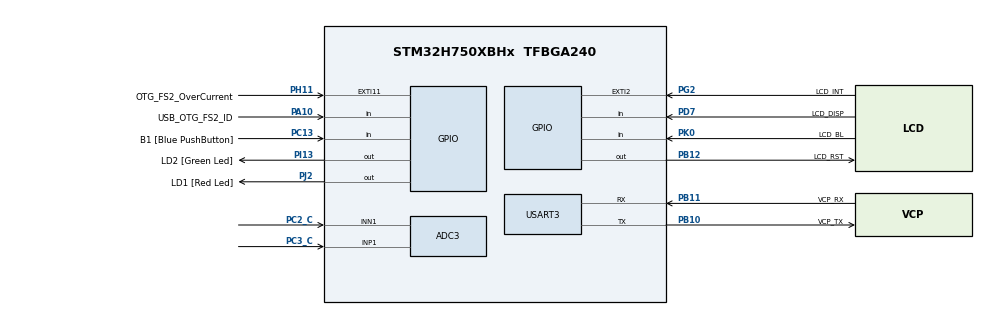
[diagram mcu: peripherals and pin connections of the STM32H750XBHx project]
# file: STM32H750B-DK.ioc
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ADC3.Channel-0\#ChannelRegularConversion=ADC_CHANNEL_1
ADC3.NbrOfConversionFlag=1
ADC3.OffsetNumber-0\#ChannelRegularConversion=ADC_OFFSET_NONE
ADC3.Rank-0\#ChannelRegularConversion=1
ADC3.SamplingTime-0\#ChannelRegularConversion=ADC_SAMPLETIME_1CYCLE_5
ADC3.SingleDiff-0\#ChannelRegularConversion=ADC_DIFFERENTIAL_ENDED
board=STM32H750B-DK
CORTEX_M7.AccessPermission-Cortex_Memory_Protection_Unit_Region0_Settings=MPU_REGION_FULL_ACCESS
CORTEX_M7.AccessPermission-Cortex_Memory_Protection_Unit_Region1_Settings=MPU_REGION_FULL_ACCESS
CORTEX_M7.BaseAddress-Cortex_Memory_Protection_Unit_Region0_Settings=0x90000000
CORTEX_M7.BaseAddress-Cortex_Memory_Protection_Unit_Region1_Settings=0xD0000000
CORTEX_M7.CPU_DCache=Enabled
CORTEX_M7.CPU_ICache=Enabled
CORTEX_M7.Enable-Cortex_Memory_Protection_Unit_Region0_Settings=MPU_REGION_ENABLE
CORTEX_M7.Enable-Cortex_Memory_Protection_Unit_Region1_Settings=MPU_REGION_ENABLE
CORTEX_M7.IsBufferable-Cortex_Memory_Protection_Unit_Region0_Settings=MPU_ACCESS_BUFFERABLE
CORTEX_M7.IsBufferable-Cortex_Memory_Protection_Unit_Region1_Settings=MPU_ACCESS_BUFFERABLE
CORTEX_M7.IsCacheable-Cortex_Memory_Protection_Unit_Region0_Settings=MPU_ACCESS_CACHEABLE
CORTEX_M7.IsCacheable-Cortex_Memory_Protection_Unit_Region1_Settings=MPU_ACCESS_CACHEABLE
CORTEX_M7.MPU_Control=MPU_PRIVILEGED_DEFAULT
CORTEX_M7.Size-Cortex_Memory_Protection_Unit_Region0_Settings=MPU_REGION_SIZE_128MB
CORTEX_M7.Size-Cortex_Memory_Protection_Unit_Region1_Settings=MPU_REGION_SIZE_8MB
Mcu.Family=STM32H7
Mcu.Name=STM32H750XBHx
Mcu.Package=TFBGA240
NVIC.PriorityGroup=NVIC_PRIORITYGROUP_4
PA0_C.Signal=ADCx_INP0
PA1_C.Signal=ADCx_INP1
PA1.GPIO_Label=MII_RX_CLK
PA1.Signal=ETH_RX_CLK
PA10.GPIO_Label=USB_OTG_FS2_ID
PA10.Signal=GPIO_Input
PA11.GPIO_Label=USB_OTG_FS2_N
PA11.Signal=USB_OTG_FS_DM
PA12.GPIO_Label=USB_OTG_FS2_P
PA12.Signal=USB_OTG_FS_DP
PA2.GPIO_Label=MII_MDIO
PA2.Signal=ETH_MDIO
PA6.Signal=S_TIM13_CH1
PA7.GPIO_Label=MII_RX_DV
PA7.Signal=ETH_RX_DV
PA8.Signal=S_TIM1_CH1
PA9.GPIO_Label=VBUS_FS2
PA9.Signal=USB_OTG_FS_VBUS
PB0.GPIO_Label=MII_RX_D2
PB0.Signal=ETH_RXD2
PB1.GPIO_Label=MII_RX_D3
PB1.Signal=ETH_RXD3
PB10.GPIO_Label=VCP_TX
PB10.Mode=Asynchronous
PB10.Signal=USART3_TX
PB11.GPIO_Label=VCP_RX
PB11.GPIO_PuPd=GPIO_PULLUP
PB11.Mode=Asynchronous
PB11.Signal=USART3_RX
PB12.GPIO_Label=LCD_RST
PB12.Signal=GPIO_Output
PB13.GPIO_Label=FDCAN2_TX
PB13.Signal=FDCAN2_TX
PB15.Signal=SPI2_MOSI
PB4\ (NJTRST).Signal=SPI2_NSS
PB5.GPIO_Label=FDCAN2_RX
PB5.Signal=FDCAN2_RX
PB6.Signal=QUADSPI_BK1_NCS
PB8.GPIO_Label=SDIO1_D4
PB8.Signal=SDMMC1_D4
PB9.GPIO_Label=SDIO1_D5
PB9.Signal=SDMMC1_D5
PC0.Signal=ADCx_INP10
PC1.GPIO_Label=MII_MDC
PC1.Signal=ETH_MDC
PC10.GPIO_Label=SDIO1_D2
PC10.Signal=SDMMC1_D2
PC11.GPIO_Label=SDIO1_D3
PC11.Signal=SDMMC1_D3
PC12.GPIO_Label=SDIO1_CK
PC12.Signal=SDMMC1_CK
PC13.GPIO_Label=B1 [Blue PushButton]
PC13.Signal=GPIO_Input
PC14-OSC32_IN\ (OSC32_IN).GPIO_Label=OSC32_IN
PC14-OSC32_IN\ (OSC32_IN).Mode=LSE-External-Oscillator
PC14-OSC32_IN\ (OSC32_IN).Signal=RCC_OSC32_IN
PC15-OSC32_OUT\ (OSC32_OUT).GPIO_Label=OSC32_OUT
PC15-OSC32_OUT\ (OSC32_OUT).Mode=LSE-External-Oscillator
PC15-OSC32_OUT\ (OSC32_OUT).Signal=RCC_OSC32_OUT
PC2_C.Signal=SharedAnalog_PC2
PC2.GPIO_Label=MII_TXD2
PC2.Signal=ETH_TXD2
PC3_C.Mode=IN1-Differential
PC3_C.Signal=ADC3_INP1
PC3.GPIO_Label=MII_TX_CLK
PC3.Signal=ETH_TX_CLK
PC4.GPIO_Label=MII_RXD0
PC4.Signal=ETH_RXD0
PC5.GPIO_Label=MII_RXD1
PC5.Signal=ETH_RXD1
PC6.GPIO_Label=SDIO1_D6
PC6.Signal=SDMMC1_D6
PC7.GPIO_Label=SDIO1_D7
PC7.Signal=SDMMC1_D7
PC8.GPIO_Label=SDIO1_D0
PC8.Signal=SDMMC1_D0
PC9.GPIO_Label=SDIO1_D1
PC9.Signal=SDMMC1_D1
PD0.Signal=FMC_D2_DA2
PD1.Signal=FMC_D3_DA3
PD10.Signal=FMC_D15_DA15
PD11.Signal=QUADSPI_BK1_IO0
PD14.Signal=FMC_D0_DA0
PD15.Signal=FMC_D1_DA1
PD2.GPIO_Label=SDIO1_CMD
PD2.Signal=SDMMC1_CMD
PD3.Signal=SPI2_SCK
PD7.GPIO_Label=LCD_DISP
PD7.Signal=GPIO_Input
PD8.Signal=FMC_D13_DA13
PD9.Signal=FMC_D14_DA14
PE0.Signal=FMC_NBL0
PE1.Signal=FMC_NBL1
PE10.Signal=FMC_D7_DA7
PE11.Signal=FMC_D8_DA8
PE12.Signal=FMC_D9_DA9
PE13.Signal=FMC_D10_DA10
PE14.Signal=FMC_D11_DA11
PE15.Signal=FMC_D12_DA12
PE2.GPIO_Label=MII_TXD3
PE2.Signal=ETH_TXD3
PE4.Signal=SAI4_D2
PE5.Signal=SAI4_CK2
PE7.Signal=FMC_D4_DA4
PE8.Signal=FMC_D5_DA5
PE9.Signal=FMC_D6_DA6
PF0.Signal=FMC_A0
PF1.Signal=FMC_A1
PF10.Signal=QUADSPI_CLK
PF11.Signal=FMC_SDNRAS
PF12.Signal=FMC_A6
PF13.Signal=FMC_A7
PF14.Signal=FMC_A8
PF15.Signal=FMC_A9
PF2.Signal=FMC_A2
PF3.Signal=FMC_A3
PF4.Signal=FMC_A4
PF5.Signal=FMC_A5
PF6.Signal=QUADSPI_BK1_IO3
PF7.Signal=QUADSPI_BK1_IO2
PF8.Signal=ADC3_INP7
PF9.Signal=QUADSPI_BK1_IO1
PG0.Signal=FMC_A10
PG1.Signal=FMC_A11
PG10.Signal=SAI2_SD_B
PG11.GPIO_Label=MII_TX_EN
PG11.Signal=ETH_TX_EN
PG12.GPIO_Label=MII_TXD1
PG12.Signal=ETH_TXD1
PG13.GPIO_Label=MII_TXD0
PG13.Signal=ETH_TXD0
PG15.Signal=FMC_SDNCAS
PG2.GPIO_Label=LCD_INT
PG2.Signal=GPXTI2
PG4.Signal=FMC_A14_BA0
PG5.Signal=FMC_A15_BA1
PG8.Signal=FMC_SDCLK
PH0-OSC_IN\ (PH0).GPIO_Label=OSC_IN
PH0-OSC_IN\ (PH0).Mode=HSE-External-Oscillator
PH0-OSC_IN\ (PH0).Signal=RCC_OSC_IN
PH1-OSC_OUT\ (PH1).GPIO_Label=OSC_OUT
PH1-OSC_OUT\ (PH1).Mode=HSE-External-Oscillator
PH1-OSC_OUT\ (PH1).Signal=RCC_OSC_OUT
PH11.GPIO_Label=OTG_FS2_OverCurrent
PH11.Signal=GPXTI11
PH13.GPIO_Label=FDCAN1_TX
PH13.Signal=FDCAN1_TX
PH14.GPIO_Label=FDCAN1_RX
PH14.Signal=FDCAN1_RX
PH15.Signal=TIM8_CH3N
PH2.GPIO_Label=MII_CRS
PH2.Signal=ETH_CRS
PH3.GPIO_Label=MII_COL
PH3.Signal=ETH_COL
PH5.Signal=FMC_SDNWE
PH6.Signal=FMC_SDNE1
PH7.Signal=FMC_SDCKE1
PH9.Signal=LTDC_R3
PI0.Signal=LTDC_G5
PI1.Signal=LTDC_G6
PI10.GPIO_Label=MII_RX_ER
PI10.Signal=ETH_RX_ER
PI12.Signal=LTDC_HSYNC
PI13.GPIO_Label=LD2 [Green Led]
PI13.Signal=GPIO_Output
PI14.Signal=LTDC_CLK
PI15.Signal=LTDC_R0
PI2.Signal=SPI2_MISO
PI4.Signal=SAI2_MCLK_A
PI5.Signal=SAI2_SCK_A
PI6.Signal=SAI2_SD_A
PI7.Signal=SAI2_FS_A
PI9.Signal=LTDC_VSYNC
PJ0.Signal=LTDC_R1
PJ1.Signal=LTDC_R2
PJ10.Signal=LTDC_G3
PJ11.Signal=LTDC_G4
PJ12.Signal=LTDC_B0
PJ13.Signal=LTDC_B1
PJ14.Signal=LTDC_B2
PJ15.GPIO_Label=LCD_DISP
PJ15.Signal=LTDC_B3
PJ2.GPIO_Label=LD1 [Red Led]
PJ2.Signal=GPIO_Output
PJ3.Signal=LTDC_R4
PJ4.Signal=LTDC_R5
PJ5.Signal=LTDC_R6
PJ6.Signal=LTDC_R7
PJ7.Signal=LTDC_G0
PJ8.Signal=LTDC_G1
PJ9.Signal=LTDC_G2
PK0.GPIO_Label=LCD_BL
PK0.Signal=GPIO_Input
PK2.Signal=LTDC_G7
PK3.Signal=LTDC_B4
PK4.Signal=LTDC_B5
PK5.Signal=LTDC_B6
PK6.Signal=LTDC_B7
PK7.Signal=LTDC_DE
ProjectManager.HeapSize=0x800
ProjectManager.StackSize=0x800
ProjectManager.TargetToolchain=STM32CubeIDE
RCC.ADCCLockSelection=RCC_ADCCLKSOURCE_PLL3
RCC.ADCFreq_Value=80000000
RCC.APB1Freq_Value=120000000
RCC.APB2Freq_Value=120000000
RCC.APB3Freq_Value=120000000
RCC.APB4Freq_Value=120000000
RCC.CortexFreq_Value=480000000
RCC.D1PPRE=RCC_APB3_DIV2
RCC.D2PPRE1=RCC_APB1_DIV2
RCC.D2PPRE2=RCC_APB2_DIV2
RCC.D3PPRE=RCC_APB4_DIV2
RCC.DIVM1=5
RCC.DIVM2=2
RCC.DIVM3=5
RCC.DIVN1=192
RCC.DIVN2=24
RCC.DIVN3=32
RCC.DIVP2=4
RCC.DIVQ1=4
RCC.HCLKFreq_Value=240000000
RCC.HPRE=RCC_HCLK_DIV2
RCC.PLL2FRACN=0
RCC.PLL3FRACN=0
RCC.PLLFRACN=0
RCC.PLLSourceVirtual=RCC_PLLSOURCE_HSE
RCC.PWR_Regulator_Voltage_Scale=PWR_REGULATOR_VOLTAGE_SCALE0
RCC.SAI1CLockSelection=RCC_SAI1CLKSOURCE_PLL2
RCC.SYSCLKFreq_VALUE=480000000
RCC.SYSCLKSource=RCC_SYSCLKSOURCE_PLLCLK
RCC.USBCLockSelection=RCC_USBCLKSOURCE_HSI48
RCC.USBFreq_Value=48000000
SH.ADCx_INP0.0=ADC1_INP0
SH.ADCx_INP0.1=ADC2_INP0
SH.ADCx_INP1.0=ADC1_INP1
SH.ADCx_INP1.1=ADC2_INP1
SH.ADCx_INP10.0=ADC1_INP10
SH.ADCx_INP10.1=ADC3_INP10
SH.FMC_A0.0=FMC_A0
SH.FMC_A1.0=FMC_A1
SH.FMC_A10.0=FMC_A10
SH.FMC_A11.0=FMC_A11
SH.FMC_A14_BA0.0=FMC_BA0
SH.FMC_A15_BA1.0=FMC_BA1
SH.FMC_A2.0=FMC_A2
SH.FMC_A3.0=FMC_A3
SH.FMC_A4.0=FMC_A4
SH.FMC_A5.0=FMC_A5
SH.FMC_A6.0=FMC_A6
SH.FMC_A7.0=FMC_A7
SH.FMC_A8.0=FMC_A8
SH.FMC_A9.0=FMC_A9
SH.FMC_D0_DA0.0=FMC_D0
SH.FMC_D1_DA1.0=FMC_D1
SH.FMC_D10_DA10.0=FMC_D10
SH.FMC_D11_DA11.0=FMC_D11
SH.FMC_D12_DA12.0=FMC_D12
SH.FMC_D13_DA13.0=FMC_D13
SH.FMC_D14_DA14.0=FMC_D14
SH.FMC_D15_DA15.0=FMC_D15
SH.FMC_D2_DA2.0=FMC_D2
SH.FMC_D3_DA3.0=FMC_D3
SH.FMC_D4_DA4.0=FMC_D4
SH.FMC_D5_DA5.0=FMC_D5
SH.FMC_D6_DA6.0=FMC_D6
SH.FMC_D7_DA7.0=FMC_D7
SH.FMC_D8_DA8.0=FMC_D8
SH.FMC_D9_DA9.0=FMC_D9
SH.FMC_NBL0.0=FMC_NBL0
SH.FMC_NBL1.0=FMC_NBL1
SH.FMC_SDCLK.0=FMC_SDCLK
SH.FMC_SDNCAS.0=FMC_SDNCAS
SH.FMC_SDNRAS.0=FMC_SDNRAS
SH.FMC_SDNWE.0=FMC_SDNWE
SH.S_TIM1_CH1.0=TIM1_CH1
SH.S_TIM13_CH1.0=TIM13_CH1
SH.SharedAnalog_PC2.0=ADC3_INP0
SH.SharedAnalog_PC2.1=ADC3_INN1,IN1-Differential
STMicroelectronics.X-CUBE-AI.9.1.0.actBufferSize=528
STMicroelectronics.X-CUBE-AI.9.1.0.ActivationBuffers=(ai_handle)0xD0000000
STMicroelectronics.X-CUBE-AI.9.1.0.ActivationBufferSizeList=3760
STMicroelectronics.X-CUBE-AI.9.1.0.ActivationPragmas=AI_EXTERNAL_SDRAM
STMicroelectronics.X-CUBE-AI.9.1.0.ApplicationCcDeviceJjApplication=SystemPerformance
STMicroelectronics.X-CUBE-AI.9.1.0.BSP.number=1
STMicroelectronics.X-CUBE-AI.9.1.0.bspIncludes=stm32h750b_discovery_qspi.h,stm32h750b_discovery_errno.h,stm32h750b_discovery_errno.h,stm32h750b_discovery_sdram.h
STMicroelectronics.X-CUBE-AI.9.1.0.copyWeightToRam=false
STMicroelectronics.X-CUBE-AI.9.1.0.copyWeightToRam-927db2e8043154add13b426688e4f66e730f1de616e50d16bf0c6b745113b24c=false
STMicroelectronics.X-CUBE-AI.9.1.0.customLayerConfigEnabled=false
STMicroelectronics.X-CUBE-AI.9.1.0.customLayerConfigEnabled-927db2e8043154add13b426688e4f66e730f1de616e50d16bf0c6b745113b24c=false
STMicroelectronics.X-CUBE-AI.9.1.0.ExternalRamActivationBufferMaxSize=3760
STMicroelectronics.X-CUBE-AI.9.1.0.ExternalRamActivationBufferStartAddr=0xD0000000
STMicroelectronics.X-CUBE-AI.9.1.0.extFlashDriver=External NOR Flash
STMicroelectronics.X-CUBE-AI.9.1.0.extFlashDriver-927db2e8043154add13b426688e4f66e730f1de616e50d16bf0c6b745113b24c=External NOR Flash
STMicroelectronics.X-CUBE-AI.9.1.0.extFlashSize=128
STMicroelectronics.X-CUBE-AI.9.1.0.extFlashSize-927db2e8043154add13b426688e4f66e730f1de616e50d16bf0c6b745113b24c=128
STMicroelectronics.X-CUBE-AI.9.1.0.extFlashStartAddr=0x90000000
STMicroelectronics.X-CUBE-AI.9.1.0.extFlashStartAddr-927db2e8043154add13b426688e4f66e730f1de616e50d16bf0c6b745113b24c=0x90000000
STMicroelectronics.X-CUBE-AI.9.1.0.extRamDriver=External SDRAM
STMicroelectronics.X-CUBE-AI.9.1.0.extRamDriver-927db2e8043154add13b426688e4f66e730f1de616e50d16bf0c6b745113b24c=External SDRAM
STMicroelectronics.X-CUBE-AI.9.1.0.extRamStartAddr=0xD0000000
STMicroelectronics.X-CUBE-AI.9.1.0.extRamStartAddr-927db2e8043154add13b426688e4f66e730f1de616e50d16bf0c6b745113b24c=0xD0000000
STMicroelectronics.X-CUBE-AI.9.1.0.HeapSize=0x800
STMicroelectronics.X-CUBE-AI.9.1.0.initFunctions=BSP_QSPI_Init_t qspiInit;\:qspiInit.InterfaceMode\=MT25TL01G_QPI_MODE;\:qspiInit.TransferRate\= MT25TL01G_DTR_TRANSFER ;\:qspiInit.DualFlashMode\= MT25TL01G_DUALFLASH_ENABLE;\:BSP_QSPI_Init(0,&qspiInit);\:BSP_QSPI_EnableMemoryMappedMode(0);\:BSP_SDRAM_Init(0);
STMicroelectronics.X-CUBE-AI.9.1.0.MaximumNumberOfInputLayer=1
STMicroelectronics.X-CUBE-AI.9.1.0.maximumNumberOfInputLayer=1
STMicroelectronics.X-CUBE-AI.9.1.0.MaximumNumberOfOutputLayer=1
STMicroelectronics.X-CUBE-AI.9.1.0.maximumNumberOfOutputLayer=1
STMicroelectronics.X-CUBE-AI.9.1.0.MaximumSizeOfInputLayer=1
STMicroelectronics.X-CUBE-AI.9.1.0.MaximumSizeOfOutputLayer=1
STMicroelectronics.X-CUBE-AI.9.1.0.memoryPool0driver-927db2e8043154add13b426688e4f66e730f1de616e50d16bf0c6b745113b24c=DTCMRAM
STMicroelectronics.X-CUBE-AI.9.1.0.memoryPool0id-927db2e8043154add13b426688e4f66e730f1de616e50d16bf0c6b745113b24c=0
STMicroelectronics.X-CUBE-AI.9.1.0.memoryPool0max-927db2e8043154add13b426688e4f66e730f1de616e50d16bf0c6b745113b24c=128
STMicroelectronics.X-CUBE-AI.9.1.0.memoryPool0name-927db2e8043154add13b426688e4f66e730f1de616e50d16bf0c6b745113b24c=POOL_0_DTCMRAM
STMicroelectronics.X-CUBE-AI.9.1.0.memoryPool0size-927db2e8043154add13b426688e4f66e730f1de616e50d16bf0c6b745113b24c=124
STMicroelectronics.X-CUBE-AI.9.1.0.memoryPool0start-927db2e8043154add13b426688e4f66e730f1de616e50d16bf0c6b745113b24c=0x20000000
STMicroelectronics.X-CUBE-AI.9.1.0.memoryPool0used-927db2e8043154add13b426688e4f66e730f1de616e50d16bf0c6b745113b24c=0
STMicroelectronics.X-CUBE-AI.9.1.0.memoryPool1driver-927db2e8043154add13b426688e4f66e730f1de616e50d16bf0c6b745113b24c=RAM_D1
STMicroelectronics.X-CUBE-AI.9.1.0.memoryPool1id-927db2e8043154add13b426688e4f66e730f1de616e50d16bf0c6b745113b24c=1
STMicroelectronics.X-CUBE-AI.9.1.0.memoryPool1max-927db2e8043154add13b426688e4f66e730f1de616e50d16bf0c6b745113b24c=512
STMicroelectronics.X-CUBE-AI.9.1.0.memoryPool1name-927db2e8043154add13b426688e4f66e730f1de616e50d16bf0c6b745113b24c=POOL_1_RAM_D1
STMicroelectronics.X-CUBE-AI.9.1.0.memoryPool1size-927db2e8043154add13b426688e4f66e730f1de616e50d16bf0c6b745113b24c=484
STMicroelectronics.X-CUBE-AI.9.1.0.memoryPool1start-927db2e8043154add13b426688e4f66e730f1de616e50d16bf0c6b745113b24c=0x24000000
STMicroelectronics.X-CUBE-AI.9.1.0.memoryPool1used-927db2e8043154add13b426688e4f66e730f1de616e50d16bf0c6b745113b24c=0
STMicroelectronics.X-CUBE-AI.9.1.0.memoryPool2driver-927db2e8043154add13b426688e4f66e730f1de616e50d16bf0c6b745113b24c=RAM_D2
STMicroelectronics.X-CUBE-AI.9.1.0.memoryPool2id-927db2e8043154add13b426688e4f66e730f1de616e50d16bf0c6b745113b24c=2
STMicroelectronics.X-CUBE-AI.9.1.0.memoryPool2max-927db2e8043154add13b426688e4f66e730f1de616e50d16bf0c6b745113b24c=288
STMicroelectronics.X-CUBE-AI.9.1.0.memoryPool2name-927db2e8043154add13b426688e4f66e730f1de616e50d16bf0c6b745113b24c=POOL_2_RAM_D2
STMicroelectronics.X-CUBE-AI.9.1.0.memoryPool2size-927db2e8043154add13b426688e4f66e730f1de616e50d16bf0c6b745113b24c=288
STMicroelectronics.X-CUBE-AI.9.1.0.memoryPool2start-927db2e8043154add13b426688e4f66e730f1de616e50d16bf0c6b745113b24c=0x30000000
STMicroelectronics.X-CUBE-AI.9.1.0.memoryPool2used-927db2e8043154add13b426688e4f66e730f1de616e50d16bf0c6b745113b24c=0
STMicroelectronics.X-CUBE-AI.9.1.0.memoryPool3driver-927db2e8043154add13b426688e4f66e730f1de616e50d16bf0c6b745113b24c=RAM_D3
STMicroelectronics.X-CUBE-AI.9.1.0.memoryPool3id-927db2e8043154add13b426688e4f66e730f1de616e50d16bf0c6b745113b24c=3
STMicroelectronics.X-CUBE-AI.9.1.0.memoryPool3max-927db2e8043154add13b426688e4f66e730f1de616e50d16bf0c6b745113b24c=64
STMicroelectronics.X-CUBE-AI.9.1.0.memoryPool3name-927db2e8043154add13b426688e4f66e730f1de616e50d16bf0c6b745113b24c=POOL_3_RAM_D3
STMicroelectronics.X-CUBE-AI.9.1.0.memoryPool3size-927db2e8043154add13b426688e4f66e730f1de616e50d16bf0c6b745113b24c=64
STMicroelectronics.X-CUBE-AI.9.1.0.memoryPool3start-927db2e8043154add13b426688e4f66e730f1de616e50d16bf0c6b745113b24c=0x38000000
STMicroelectronics.X-CUBE-AI.9.1.0.memoryPool3used-927db2e8043154add13b426688e4f66e730f1de616e50d16bf0c6b745113b24c=0
STMicroelectronics.X-CUBE-AI.9.1.0.memoryPool4driver-927db2e8043154add13b426688e4f66e730f1de616e50d16bf0c6b745113b24c=External SDRAM
STMicroelectronics.X-CUBE-AI.9.1.0.memoryPool4id-927db2e8043154add13b426688e4f66e730f1de616e50d16bf0c6b745113b24c=4
STMicroelectronics.X-CUBE-AI.9.1.0.memoryPool4max-927db2e8043154add13b426688e4f66e730f1de616e50d16bf0c6b745113b24c=8192
STMicroelectronics.X-CUBE-AI.9.1.0.memoryPool4name-927db2e8043154add13b426688e4f66e730f1de616e50d16bf0c6b745113b24c=POOL_EXTERNAL_SDRAM
STMicroelectronics.X-CUBE-AI.9.1.0.memoryPool4size-927db2e8043154add13b426688e4f66e730f1de616e50d16bf0c6b745113b24c=8192
STMicroelectronics.X-CUBE-AI.9.1.0.memoryPool4start-927db2e8043154add13b426688e4f66e730f1de616e50d16bf0c6b745113b24c=0xd0000000
STMicroelectronics.X-CUBE-AI.9.1.0.memoryPool4used-927db2e8043154add13b426688e4f66e730f1de616e50d16bf0c6b745113b24c=0
STMicroelectronics.X-CUBE-AI.9.1.0.ModelActualCompression-927db2e8043154add13b426688e4f66e730f1de616e50d16bf0c6b745113b24c=0.0
STMicroelectronics.X-CUBE-AI.9.1.0.ModelCompression-927db2e8043154add13b426688e4f66e730f1de616e50d16bf0c6b745113b24c=Lossless
STMicroelectronics.X-CUBE-AI.9.1.0.ModelFlashOccupation-927db2e8043154add13b426688e4f66e730f1de616e50d16bf0c6b745113b24c=26866
STMicroelectronics.X-CUBE-AI.9.1.0.ModelHashList=927db2e8043154add13b426688e4f66e730f1de616e50d16bf0c6b745113b24c
STMicroelectronics.X-CUBE-AI.9.1.0.ModelKind-927db2e8043154add13b426688e4f66e730f1de616e50d16bf0c6b745113b24c=ONNX
STMicroelectronics.X-CUBE-AI.9.1.0.ModelMacc-927db2e8043154add13b426688e4f66e730f1de616e50d16bf0c6b745113b24c=4013
STMicroelectronics.X-CUBE-AI.9.1.0.ModelName-927db2e8043154add13b426688e4f66e730f1de616e50d16bf0c6b745113b24c=network
STMicroelectronics.X-CUBE-AI.9.1.0.ModelNameList=network
STMicroelectronics.X-CUBE-AI.9.1.0.ModelRamOccupation-927db2e8043154add13b426688e4f66e730f1de616e50d16bf0c6b745113b24c=2512
STMicroelectronics.X-CUBE-AI.9.1.0.ModelStructureFile-927db2e8043154add13b426688e4f66e730f1de616e50d16bf0c6b745113b24c=mnist_model-2_PerChannel_quant_random_1.onnx
STMicroelectronics.X-CUBE-AI.9.1.0.ModelType-927db2e8043154add13b426688e4f66e730f1de616e50d16bf0c6b745113b24c=Saved model
STMicroelectronics.X-CUBE-AI.9.1.0.noOnnxIoTranspose=false
STMicroelectronics.X-CUBE-AI.9.1.0.ProjectManager.HeapSize=0x800
STMicroelectronics.X-CUBE-AI.9.1.0.ProjectManager.StackSize=0x800
STMicroelectronics.X-CUBE-AI.9.1.0.splitWeigths=true
STMicroelectronics.X-CUBE-AI.9.1.0.splitWeigths-927db2e8043154add13b426688e4f66e730f1de616e50d16bf0c6b745113b24c=true
STMicroelectronics.X-CUBE-AI.9.1.0.StackSize=0x800
STMicroelectronics.X-CUBE-AI.9.1.0.tensorsInExternalFlash=_Relu_output_0_weights
STMicroelectronics.X-CUBE-AI.9.1.0.tensorsInExternalFlash-927db2e8043154add13b426688e4f66e730f1de616e50d16bf0c6b745113b24c=_Relu_output_0_weights
STMicroelectronics.X-CUBE-AI.9.1.0.useActivationBuffer=true
STMicroelectronics.X-CUBE-AI.9.1.0.useActivationBuffer-927db2e8043154add13b426688e4f66e730f1de616e50d16bf0c6b745113b24c=true
STMicroelectronics.X-CUBE-AI.9.1.0.useExternalFlash=true
STMicroelectronics.X-CUBE-AI.9.1.0.useExternalFlash-927db2e8043154add13b426688e4f66e730f1de616e50d16bf0c6b745113b24c=true
STMicroelectronics.X-CUBE-AI.9.1.0.useExternalRam=true
STMicroelectronics.X-CUBE-AI.9.1.0.useExternalRam-927db2e8043154add13b426688e4f66e730f1de616e50d16bf0c6b745113b24c=true
STMicroelectronics.X-CUBE-AI.9.1.0.useInputAllocation=true
STMicroelectronics.X-CUBE-AI.9.1.0.useInputAllocation-927db2e8043154add13b426688e4f66e730f1de616e50d16bf0c6b745113b24c=true
STMicroelectronics.X-CUBE-AI.9.1.0.useOutputAllocation=true
STMicroelectronics.X-CUBE-AI.9.1.0.useOutputAllocation-927db2e8043154add13b426688e4f66e730f1de616e50d16bf0c6b745113b24c=true
STMicroelectronics.X-CUBE-AI.9.1.0.WorkingBufferStartAddr=0xD0000000
STMicroelectronics.X-CUBE-AI.9.1.0.WorkingBufferStartAddrList=0xD0000000
STMicroelectronics.X-CUBE-AI.9.1.0.XAaCUBEAaAICcArtificialOoIntelligenceJjCore=true
STMicroelectronics.X-CUBE-AI.9.1.00.BSP.api=Unknown
STMicroelectronics.X-CUBE-AI.9.1.00.BSP.condition=\!SEMDeviceJjApplicationJjApplicationTemplate
STMicroelectronics.X-CUBE-AI.9.1.00.BSP.instance=USART3
STMicroelectronics.X-CUBE-AI.9.1.00.BSP.ip=USART
STMicroelectronics.X-CUBE-AI.9.1.00.BSP.mode=Asynchronous
STMicroelectronics.X-CUBE-AI.9.1.00.BSP.name=COM Port
STMicroelectronics.X-CUBE-AI.9.1.00.BSP.solution=USART3
STMicroelectronics.X-CUBE-AI.9.1.00.BSP.STBoard=false
USART3.VirtualMode-Asynchronous=VM_ASYNC
VP_STMicroelectronics.X-CUBE-AI_VS_ArtificialOoIntelligenceJjXAaCUBEAaAI_9.1.0.Mode=ArtificialOoIntelligenceJjXAaCUBEAaAI
VP_STMicroelectronics.X-CUBE-AI_VS_DeviceJjApplication_9.1.0.Mode=DeviceJjApplication

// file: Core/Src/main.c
/* USER CODE BEGIN Header */
/**
  ******************************************************************************
  * @file           : main.c
  * @brief          : Main program body
  ******************************************************************************
  * @attention
  *
  * Copyright (c) 2024 STMicroelectronics.
  * All rights reserved.
  *
  * This software is licensed under terms that can be found in the LICENSE file
  * in the root directory of this software component.
  * If no LICENSE file comes with this software, it is provided AS-IS.
  *
  ******************************************************************************
  */
/* USER CODE END Header */
#include "main.h"
#include "app_x-cube-ai.h"

/* USER CODE BEGIN Includes */
#include "network.h"
#include "network_data.h"
#include "mnist_test_subset-100b.h"
/* USER CODE END Includes */

ADC_HandleTypeDef hadc3;

UART_HandleTypeDef huart3;

/* USER CODE BEGIN PV */
const signed char (*mnist_test)[784] = mnist_test_subset_quantized;
const unsigned char*  mnist_test_labels = mnist_test_subset_labels;

ai_handle network = AI_HANDLE_NULL;           // Handle to network instance
AI_ALIGNED(4) ai_u8 activations[AI_NETWORK_DATA_ACTIVATIONS_SIZE];  // Activation buffer
ai_network_report report;
// input/output data
//ai_i8 *input_data = (ai_i8*)mnist_test_subset_quantized;  // Your test subset input data
AI_ALIGNED(4) ai_i8 network_output[AI_NETWORK_OUT_1_SIZE];
AI_ALIGNED(4) ai_i8 network_input[AI_NETWORK_IN_1_SIZE];
uint8_t recognized_digits[MNIST_TEST_SUBSET_SIZE] = {0};

extern ai_handle data_activations0[];

int success = 0;
float accuracy = 0.0;
char buffer[100];
/* USER CODE END PV */

void SystemClock_Config(void);
static void MPU_Config(void);
static void MX_GPIO_Init(void);
static void MX_ADC3_Init(void);
/* USER CODE BEGIN PFP */
ai_bool pa3_ai_network_init(void);
ai_i32 pa3_ai_network_inference(ai_i8 *input_data, ai_i8 *output_data);
void UART_SendString(UART_HandleTypeDef* huart, const char *str);
void pa3_run_model_on_test_dataset(void);
/* USER CODE END PFP */

int main(void)
{

  /* MPU Configuration--------------------------------------------------------*/
  MPU_Config();

  /* Enable the CPU Cache */

  /* Enable I-Cache---------------------------------------------------------*/
  SCB_EnableICache();

  /* Enable D-Cache---------------------------------------------------------*/
  SCB_EnableDCache();

  /* MCU Configuration--------------------------------------------------------*/

  /* Reset of all peripherals, Initializes the Flash interface and the Systick. */
  HAL_Init();

  /* Configure the system clock */
  SystemClock_Config();

  /* Initialize all configured peripherals */
  MX_GPIO_Init();
  MX_ADC3_Init();
  //MX_X_CUBE_AI_Init();
  /* USER CODE BEGIN 2 */
  MX_USART3_UART_Init();
  BSP_QSPI_Init_t qspiInit;
  qspiInit.InterfaceMode=MT25TL01G_QPI_MODE;
  qspiInit.TransferRate= MT25TL01G_DTR_TRANSFER ;
  qspiInit.DualFlashMode= MT25TL01G_DUALFLASH_ENABLE;
  BSP_QSPI_Init(0,&qspiInit);
  BSP_QSPI_EnableMemoryMappedMode(0);
  BSP_SDRAM_Init(0);

  HAL_Delay(4000);
  UART_SendString(&huart3, "Initializing network...\n");
  HAL_Delay(300);
  if (!pa3_ai_network_init()) {
    // Handle initialization error
    UART_SendString(&huart3, "   Error initializing network.\n");
    __NOP();
    return -1;
  }

  UART_SendString(&huart3, "Network initialized.\n");
  ai_network_get_info(network, &report);
  sprintf(buffer, "   Network name: %s \n", report.model_name);
  UART_SendString(&huart3, buffer);
  sprintf(buffer, "   Network runtime version: %d.%d.%d \n", report.runtime_version.major, report.runtime_version.minor, report.runtime_version.micro);
  UART_SendString(&huart3, buffer);
  /* USER CODE END 2 */

  /* Infinite loop */
  while (1)
  {

    //MX_X_CUBE_AI_Process();

    /* USER CODE BEGIN 3 */
    pa3_run_model_on_test_dataset();
    HAL_Delay(200);
  }
  /* USER CODE END 3 */
}

void SystemClock_Config(void)
{
  RCC_OscInitTypeDef RCC_OscInitStruct = {0};
  RCC_ClkInitTypeDef RCC_ClkInitStruct = {0};

  /** Supply configuration update enable
  */
  HAL_PWREx_ConfigSupply(PWR_LDO_SUPPLY);

  /** Configure the main internal regulator output voltage
  */
  __HAL_PWR_VOLTAGESCALING_CONFIG(PWR_REGULATOR_VOLTAGE_SCALE1);

  while(!__HAL_PWR_GET_FLAG(PWR_FLAG_VOSRDY)) {}

  __HAL_RCC_SYSCFG_CLK_ENABLE();
  __HAL_PWR_VOLTAGESCALING_CONFIG(PWR_REGULATOR_VOLTAGE_SCALE0);

  while(!__HAL_PWR_GET_FLAG(PWR_FLAG_VOSRDY)) {}

  /** Initializes the RCC Oscillators according to the specified parameters
  * in the RCC_OscInitTypeDef structure.
  */
  RCC_OscInitStruct.OscillatorType = RCC_OSCILLATORTYPE_HSE;
  RCC_OscInitStruct.HSEState = RCC_HSE_ON;
  RCC_OscInitStruct.PLL.PLLState = RCC_PLL_ON;
  RCC_OscInitStruct.PLL.PLLSource = RCC_PLLSOURCE_HSE;
  RCC_OscInitStruct.PLL.PLLM = 5;
  RCC_OscInitStruct.PLL.PLLN = 192;
  RCC_OscInitStruct.PLL.PLLP = 2;
  RCC_OscInitStruct.PLL.PLLQ = 4;
  RCC_OscInitStruct.PLL.PLLR = 2;
  RCC_OscInitStruct.PLL.PLLRGE = RCC_PLL1VCIRANGE_2;
  RCC_OscInitStruct.PLL.PLLVCOSEL = RCC_PLL1VCOWIDE;
  RCC_OscInitStruct.PLL.PLLFRACN = 0;
  if (HAL_RCC_OscConfig(&RCC_OscInitStruct) != HAL_OK)
  {
    Error_Handler();
  }

  /** Initializes the CPU, AHB and APB buses clocks
  */
  RCC_ClkInitStruct.ClockType = RCC_CLOCKTYPE_HCLK|RCC_CLOCKTYPE_SYSCLK
                              |RCC_CLOCKTYPE_PCLK1|RCC_CLOCKTYPE_PCLK2
                              |RCC_CLOCKTYPE_D3PCLK1|RCC_CLOCKTYPE_D1PCLK1;
  RCC_ClkInitStruct.SYSCLKSource = RCC_SYSCLKSOURCE_PLLCLK;
  RCC_ClkInitStruct.SYSCLKDivider = RCC_SYSCLK_DIV1;
  RCC_ClkInitStruct.AHBCLKDivider = RCC_HCLK_DIV2;
  RCC_ClkInitStruct.APB3CLKDivider = RCC_APB3_DIV2;
  RCC_ClkInitStruct.APB1CLKDivider = RCC_APB1_DIV2;
  RCC_ClkInitStruct.APB2CLKDivider = RCC_APB2_DIV2;
  RCC_ClkInitStruct.APB4CLKDivider = RCC_APB4_DIV2;

  if (HAL_RCC_ClockConfig(&RCC_ClkInitStruct, FLASH_LATENCY_4) != HAL_OK)
  {
    Error_Handler();
  }
}

static void MX_ADC3_Init(void)
{

  ADC_ChannelConfTypeDef sConfig = {0};

  /** Common config
  */
  hadc3.Instance = ADC3;
  hadc3.Init.Resolution = ADC_RESOLUTION_16B;
  hadc3.Init.ScanConvMode = ADC_SCAN_DISABLE;
  hadc3.Init.EOCSelection = ADC_EOC_SINGLE_CONV;
  hadc3.Init.LowPowerAutoWait = DISABLE;
  hadc3.Init.ContinuousConvMode = DISABLE;
  hadc3.Init.NbrOfConversion = 1;
  hadc3.Init.DiscontinuousConvMode = DISABLE;
  hadc3.Init.ExternalTrigConv = ADC_SOFTWARE_START;
  hadc3.Init.ExternalTrigConvEdge = ADC_EXTERNALTRIGCONVEDGE_NONE;
  hadc3.Init.ConversionDataManagement = ADC_CONVERSIONDATA_DR;
  hadc3.Init.Overrun = ADC_OVR_DATA_PRESERVED;
  hadc3.Init.LeftBitShift = ADC_LEFTBITSHIFT_NONE;
  hadc3.Init.OversamplingMode = DISABLE;
  if (HAL_ADC_Init(&hadc3) != HAL_OK)
  {
    Error_Handler();
  }

  /** Configure Regular Channel
  */
  sConfig.Channel = ADC_CHANNEL_1;
  sConfig.Rank = ADC_REGULAR_RANK_1;
  sConfig.SamplingTime = ADC_SAMPLETIME_1CYCLE_5;
  sConfig.SingleDiff = ADC_DIFFERENTIAL_ENDED;
  sConfig.OffsetNumber = ADC_OFFSET_NONE;
  sConfig.Offset = 0;
  sConfig.OffsetSignedSaturation = DISABLE;
  if (HAL_ADC_ConfigChannel(&hadc3, &sConfig) != HAL_OK)
  {
    Error_Handler();
  }

}

void MX_USART3_UART_Init(void)
{

  huart3.Instance = USART3;
  huart3.Init.BaudRate = 115200;
  huart3.Init.WordLength = UART_WORDLENGTH_8B;
  huart3.Init.StopBits = UART_STOPBITS_1;
  huart3.Init.Parity = UART_PARITY_NONE;
  huart3.Init.Mode = UART_MODE_TX_RX;
  huart3.Init.HwFlowCtl = UART_HWCONTROL_NONE;
  huart3.Init.OverSampling = UART_OVERSAMPLING_16;
  huart3.Init.OneBitSampling = UART_ONE_BIT_SAMPLE_DISABLE;
  huart3.Init.ClockPrescaler = UART_PRESCALER_DIV1;
  huart3.AdvancedInit.AdvFeatureInit = UART_ADVFEATURE_NO_INIT;
  if (HAL_UART_Init(&huart3) != HAL_OK)
  {
    Error_Handler();
  }
  if (HAL_UARTEx_SetTxFifoThreshold(&huart3, UART_TXFIFO_THRESHOLD_1_8) != HAL_OK)
  {
    Error_Handler();
  }
  if (HAL_UARTEx_SetRxFifoThreshold(&huart3, UART_RXFIFO_THRESHOLD_1_8) != HAL_OK)
  {
    Error_Handler();
  }
  if (HAL_UARTEx_DisableFifoMode(&huart3) != HAL_OK)
  {
    Error_Handler();
  }

}

static void MX_GPIO_Init(void)
{
  GPIO_InitTypeDef GPIO_InitStruct = {0};

  /* GPIO Ports Clock Enable */
  __HAL_RCC_GPIOI_CLK_ENABLE();
  __HAL_RCC_GPIOB_CLK_ENABLE();
  __HAL_RCC_GPIOK_CLK_ENABLE();
  __HAL_RCC_GPIOG_CLK_ENABLE();
  __HAL_RCC_GPIOC_CLK_ENABLE();
  __HAL_RCC_GPIOE_CLK_ENABLE();
  __HAL_RCC_GPIOJ_CLK_ENABLE();
  __HAL_RCC_GPIOD_CLK_ENABLE();
  __HAL_RCC_GPIOH_CLK_ENABLE();
  __HAL_RCC_GPIOA_CLK_ENABLE();
  __HAL_RCC_GPIOF_CLK_ENABLE();

  /*Configure GPIO pin Output Level */
  HAL_GPIO_WritePin(LD2_GPIO_Port, LD2_Pin, GPIO_PIN_RESET);

  /*Configure GPIO pin Output Level */
  HAL_GPIO_WritePin(LD1_GPIO_Port, LD1_Pin, GPIO_PIN_RESET);

  /*Configure GPIO pin Output Level */
  HAL_GPIO_WritePin(LCD_RST_GPIO_Port, LCD_RST_Pin, GPIO_PIN_RESET);

  /*Configure GPIO pins : PI6 PI5 PI4 PI7 */
  GPIO_InitStruct.Pin = GPIO_PIN_6|GPIO_PIN_5|GPIO_PIN_4|GPIO_PIN_7;
  GPIO_InitStruct.Mode = GPIO_MODE_AF_PP;
  GPIO_InitStruct.Pull = GPIO_NOPULL;
  GPIO_InitStruct.Speed = GPIO_SPEED_FREQ_LOW;
  GPIO_InitStruct.Alternate = GPIO_AF10_SAI2;
  HAL_GPIO_Init(GPIOI, &GPIO_InitStruct);

  /*Configure GPIO pins : FDCAN2_RX_Pin FDCAN2_TX_Pin */
  GPIO_InitStruct.Pin = FDCAN2_RX_Pin|FDCAN2_TX_Pin;
  GPIO_InitStruct.Mode = GPIO_MODE_AF_PP;
  GPIO_InitStruct.Pull = GPIO_NOPULL;
  GPIO_InitStruct.Speed = GPIO_SPEED_FREQ_LOW;
  GPIO_InitStruct.Alternate = GPIO_AF9_FDCAN2;
  HAL_GPIO_Init(GPIOB, &GPIO_InitStruct);

  /*Configure GPIO pins : PK5 PK4 PK6 PK3
                           PK7 PK2 */
  GPIO_InitStruct.Pin = GPIO_PIN_5|GPIO_PIN_4|GPIO_PIN_6|GPIO_PIN_3
                          |GPIO_PIN_7|GPIO_PIN_2;
  GPIO_InitStruct.Mode = GPIO_MODE_AF_PP;
  GPIO_InitStruct.Pull = GPIO_NOPULL;
  GPIO_InitStruct.Speed = GPIO_SPEED_FREQ_LOW;
  GPIO_InitStruct.Alternate = GPIO_AF14_LTDC;
  HAL_GPIO_Init(GPIOK, &GPIO_InitStruct);

  /*Configure GPIO pin : PG10 */
  GPIO_InitStruct.Pin = GPIO_PIN_10;
  GPIO_InitStruct.Mode = GPIO_MODE_AF_PP;
  GPIO_InitStruct.Pull = GPIO_NOPULL;
  GPIO_InitStruct.Speed = GPIO_SPEED_FREQ_LOW;
  GPIO_InitStruct.Alternate = GPIO_AF10_SAI2;
  HAL_GPIO_Init(GPIOG, &GPIO_InitStruct);

  /*Configure GPIO pins : SDIO1_D2_Pin SDIO1_D3_Pin SDIO1_CK_Pin SDIO1_D0_Pin
                           SDIO1_D1_Pin SDIO1_D7_Pin SDIO1_D6_Pin */
  GPIO_InitStruct.Pin = SDIO1_D2_Pin|SDIO1_D3_Pin|SDIO1_CK_Pin|SDIO1_D0_Pin
                          |SDIO1_D1_Pin|SDIO1_D7_Pin|SDIO1_D6_Pin;
  GPIO_InitStruct.Mode = GPIO_MODE_AF_PP;
  GPIO_InitStruct.Pull = GPIO_NOPULL;
  GPIO_InitStruct.Speed = GPIO_SPEED_FREQ_VERY_HIGH;
  GPIO_InitStruct.Alternate = GPIO_AF12_SDIO1;
  HAL_GPIO_Init(GPIOC, &GPIO_InitStruct);

  /*Configure GPIO pins : PI1 PI0 PI9 PI12
                           PI14 PI15 */
  GPIO_InitStruct.Pin = GPIO_PIN_1|GPIO_PIN_0|GPIO_PIN_9|GPIO_PIN_12
                          |GPIO_PIN_14|GPIO_PIN_15;
  GPIO_InitStruct.Mode = GPIO_MODE_AF_PP;
  GPIO_InitStruct.Pull = GPIO_NOPULL;
  GPIO_InitStruct.Speed = GPIO_SPEED_FREQ_LOW;
  GPIO_InitStruct.Alternate = GPIO_AF14_LTDC;
  HAL_GPIO_Init(GPIOI, &GPIO_InitStruct);

  /*Configure GPIO pins : PE1 PE0 PE10 PE9
                           PE11 PE12 PE15 PE8
                           PE13 PE7 PE14 */
  GPIO_InitStruct.Pin = GPIO_PIN_1|GPIO_PIN_0|GPIO_PIN_10|GPIO_PIN_9
                          |GPIO_PIN_11|GPIO_PIN_12|GPIO_PIN_15|GPIO_PIN_8
                          |GPIO_PIN_13|GPIO_PIN_7|GPIO_PIN_14;
  GPIO_InitStruct.Mode = GPIO_MODE_AF_PP;
  GPIO_InitStruct.Pull = GPIO_NOPULL;
  GPIO_InitStruct.Speed = GPIO_SPEED_FREQ_VERY_HIGH;
  GPIO_InitStruct.Alternate = GPIO_AF12_FMC;
  HAL_GPIO_Init(GPIOE, &GPIO_InitStruct);

  /*Configure GPIO pin : PB6 */
  GPIO_InitStruct.Pin = GPIO_PIN_6;
  GPIO_InitStruct.Mode = GPIO_MODE_AF_PP;
  GPIO_InitStruct.Pull = GPIO_NOPULL;
  GPIO_InitStruct.Speed = GPIO_SPEED_FREQ_LOW;
  GPIO_InitStruct.Alternate = GPIO_AF10_QUADSPI;
  HAL_GPIO_Init(GPIOB, &GPIO_InitStruct);

  /*Configure GPIO pin : PB4 */
  GPIO_InitStruct.Pin = GPIO_PIN_4;
  GPIO_InitStruct.Mode = GPIO_MODE_AF_PP;
  GPIO_InitStruct.Pull = GPIO_NOPULL;
  GPIO_InitStruct.Speed = GPIO_SPEED_FREQ_LOW;
  GPIO_InitStruct.Alternate = GPIO_AF7_SPI2;
  HAL_GPIO_Init(GPIOB, &GPIO_InitStruct);

  /*Configure GPIO pins : MII_TX_EN_Pin MII_TXD1_Pin MII_TXD0_Pin */
  GPIO_InitStruct.Pin = MII_TX_EN_Pin|MII_TXD1_Pin|MII_TXD0_Pin;
  GPIO_InitStruct.Mode = GPIO_MODE_AF_PP;
  GPIO_InitStruct.Pull = GPIO_NOPULL;
  GPIO_InitStruct.Speed = GPIO_SPEED_FREQ_LOW;
  GPIO_InitStruct.Alternate = GPIO_AF11_ETH;
  HAL_GPIO_Init(GPIOG, &GPIO_InitStruct);

  /*Configure GPIO pins : LCD_DISP_Pin PJ14 PJ12 PJ13
                           PJ11 PJ10 PJ9 PJ0
                           PJ8 PJ7 PJ6 PJ1
                           PJ5 PJ3 PJ4 */
  GPIO_InitStruct.Pin = LCD_DISP_Pin|GPIO_PIN_14|GPIO_PIN_12|GPIO_PIN_13
                          |GPIO_PIN_11|GPIO_PIN_10|GPIO_PIN_9|GPIO_PIN_0
                          |GPIO_PIN_8|GPIO_PIN_7|GPIO_PIN_6|GPIO_PIN_1
                          |GPIO_PIN_5|GPIO_PIN_3|GPIO_PIN_4;
  GPIO_InitStruct.Mode = GPIO_MODE_AF_PP;
  GPIO_InitStruct.Pull = GPIO_NOPULL;
  GPIO_InitStruct.Speed = GPIO_SPEED_FREQ_LOW;
  GPIO_InitStruct.Alternate = GPIO_AF14_LTDC;
  HAL_GPIO_Init(GPIOJ, &GPIO_InitStruct);

  /*Configure GPIO pin : PD3 */
  GPIO_InitStruct.Pin = GPIO_PIN_3;
  GPIO_InitStruct.Mode = GPIO_MODE_AF_PP;
  GPIO_InitStruct.Pull = GPIO_NOPULL;
  GPIO_InitStruct.Speed = GPIO_SPEED_FREQ_LOW;
  GPIO_InitStruct.Alternate = GPIO_AF5_SPI2;
  HAL_GPIO_Init(GPIOD, &GPIO_InitStruct);

  /*Configure GPIO pin : PI2 */
  GPIO_InitStruct.Pin = GPIO_PIN_2;
  GPIO_InitStruct.Mode = GPIO_MODE_AF_PP;
  GPIO_InitStruct.Pull = GPIO_NOPULL;
  GPIO_InitStruct.Speed = GPIO_SPEED_FREQ_LOW;
  GPIO_InitStruct.Alternate = GPIO_AF5_SPI2;
  HAL_GPIO_Init(GPIOI, &GPIO_InitStruct);

  /*Configure GPIO pin : PH15 */
  GPIO_InitStruct.Pin = GPIO_PIN_15;
  GPIO_InitStruct.Mode = GPIO_MODE_AF_PP;
  GPIO_InitStruct.Pull = GPIO_NOPULL;
  GPIO_InitStruct.Speed = GPIO_SPEED_FREQ_LOW;
  GPIO_InitStruct.Alternate = GPIO_AF3_TIM8;
  HAL_GPIO_Init(GPIOH, &GPIO_InitStruct);

  /*Configure GPIO pins : FDCAN1_RX_Pin FDCAN1_TX_Pin */
  GPIO_InitStruct.Pin = FDCAN1_RX_Pin|FDCAN1_TX_Pin;
  GPIO_InitStruct.Mode = GPIO_MODE_AF_PP;
  GPIO_InitStruct.Pull = GPIO_NOPULL;
  GPIO_InitStruct.Speed = GPIO_SPEED_FREQ_LOW;
  GPIO_InitStruct.Alternate = GPIO_AF9_FDCAN1;
  HAL_GPIO_Init(GPIOH, &GPIO_InitStruct);

  /*Configure GPIO pin : MII_TXD3_Pin */
  GPIO_InitStruct.Pin = MII_TXD3_Pin;
  GPIO_InitStruct.Mode = GPIO_MODE_AF_PP;
  GPIO_InitStruct.Pull = GPIO_NOPULL;
  GPIO_InitStruct.Speed = GPIO_SPEED_FREQ_LOW;
  GPIO_InitStruct.Alternate = GPIO_AF11_ETH;
  HAL_GPIO_Init(MII_TXD3_GPIO_Port, &GPIO_InitStruct);

  /*Configure GPIO pin : LCD_DISPD7_Pin */
  GPIO_InitStruct.Pin = LCD_DISPD7_Pin;
  GPIO_InitStruct.Mode = GPIO_MODE_INPUT;
  GPIO_InitStruct.Pull = GPIO_NOPULL;
  HAL_GPIO_Init(LCD_DISPD7_GPIO_Port, &GPIO_InitStruct);

  /*Configure GPIO pins : PE5 PE4 */
  GPIO_InitStruct.Pin = GPIO_PIN_5|GPIO_PIN_4;
  GPIO_InitStruct.Mode = GPIO_MODE_AF_PP;
  GPIO_InitStruct.Pull = GPIO_NOPULL;
  GPIO_InitStruct.Speed = GPIO_SPEED_FREQ_LOW;
  GPIO_InitStruct.Alternate = GPIO_AF10_SAI4;
  HAL_GPIO_Init(GPIOE, &GPIO_InitStruct);

  /*Configure GPIO pins : SDIO1_D5_Pin SDIO1_D4_Pin */
  GPIO_InitStruct.Pin = SDIO1_D5_Pin|SDIO1_D4_Pin;
  GPIO_InitStruct.Mode = GPIO_MODE_AF_PP;
  GPIO_InitStruct.Pull = GPIO_NOPULL;
  GPIO_InitStruct.Speed = GPIO_SPEED_FREQ_VERY_HIGH;
  GPIO_InitStruct.Alternate = GPIO_AF12_SDIO1;
  HAL_GPIO_Init(GPIOB, &GPIO_InitStruct);

  /*Configure GPIO pins : PG15 PG8 PG5 PG4
                           PG0 PG1 */
  GPIO_InitStruct.Pin = GPIO_PIN_15|GPIO_PIN_8|GPIO_PIN_5|GPIO_PIN_4
                          |GPIO_PIN_0|GPIO_PIN_1;
  GPIO_InitStruct.Mode = GPIO_MODE_AF_PP;
  GPIO_InitStruct.Pull = GPIO_NOPULL;
  GPIO_InitStruct.Speed = GPIO_SPEED_FREQ_VERY_HIGH;
  GPIO_InitStruct.Alternate = GPIO_AF12_FMC;
  HAL_GPIO_Init(GPIOG, &GPIO_InitStruct);

  /*Configure GPIO pin : SDIO1_CMD_Pin */
  GPIO_InitStruct.Pin = SDIO1_CMD_Pin;
  GPIO_InitStruct.Mode = GPIO_MODE_AF_PP;
  GPIO_InitStruct.Pull = GPIO_NOPULL;
  GPIO_InitStruct.Speed = GPIO_SPEED_FREQ_VERY_HIGH;
  GPIO_InitStruct.Alternate = GPIO_AF12_SDIO1;
  HAL_GPIO_Init(SDIO1_CMD_GPIO_Port, &GPIO_InitStruct);

  /*Configure GPIO pins : PD0 PD1 PD15 PD14
                           PD10 PD9 PD8 */
  GPIO_InitStruct.Pin = GPIO_PIN_0|GPIO_PIN_1|GPIO_PIN_15|GPIO_PIN_14
                          |GPIO_PIN_10|GPIO_PIN_9|GPIO_PIN_8;
  GPIO_InitStruct.Mode = GPIO_MODE_AF_PP;
  GPIO_InitStruct.Pull = GPIO_NOPULL;
  GPIO_InitStruct.Speed = GPIO_SPEED_FREQ_VERY_HIGH;
  GPIO_InitStruct.Alternate = GPIO_AF12_FMC;
  HAL_GPIO_Init(GPIOD, &GPIO_InitStruct);

  /*Configure GPIO pin : USB_OTG_FS2_ID_Pin */
  GPIO_InitStruct.Pin = USB_OTG_FS2_ID_Pin;
  GPIO_InitStruct.Mode = GPIO_MODE_INPUT;
  GPIO_InitStruct.Pull = GPIO_NOPULL;
  HAL_GPIO_Init(USB_OTG_FS2_ID_GPIO_Port, &GPIO_InitStruct);

  /*Configure GPIO pin : B1_Pin */
  GPIO_InitStruct.Pin = B1_Pin;
  GPIO_InitStruct.Mode = GPIO_MODE_INPUT;
  GPIO_InitStruct.Pull = GPIO_NOPULL;
  HAL_GPIO_Init(B1_GPIO_Port, &GPIO_InitStruct);

  /*Configure GPIO pin : PA8 */
  GPIO_InitStruct.Pin = GPIO_PIN_8;
  GPIO_InitStruct.Mode = GPIO_MODE_AF_PP;
  GPIO_InitStruct.Pull = GPIO_NOPULL;
  GPIO_InitStruct.Speed = GPIO_SPEED_FREQ_LOW;
  GPIO_InitStruct.Alternate = GPIO_AF1_TIM1;
  HAL_GPIO_Init(GPIOA, &GPIO_InitStruct);

  /*Configure GPIO pins : USB_OTG_FS2_P_Pin USB_OTG_FS2_N_Pin */
  GPIO_InitStruct.Pin = USB_OTG_FS2_P_Pin|USB_OTG_FS2_N_Pin;
  GPIO_InitStruct.Mode = GPIO_MODE_AF_PP;
  GPIO_InitStruct.Pull = GPIO_NOPULL;
  GPIO_InitStruct.Speed = GPIO_SPEED_FREQ_LOW;
  GPIO_InitStruct.Alternate = GPIO_AF10_OTG1_FS;
  HAL_GPIO_Init(GPIOA, &GPIO_InitStruct);

  /*Configure GPIO pin : MII_RX_ER_Pin */
  GPIO_InitStruct.Pin = MII_RX_ER_Pin;
  GPIO_InitStruct.Mode = GPIO_MODE_AF_PP;
  GPIO_InitStruct.Pull = GPIO_NOPULL;
  GPIO_InitStruct.Speed = GPIO_SPEED_FREQ_LOW;
  GPIO_InitStruct.Alternate = GPIO_AF11_ETH;
  HAL_GPIO_Init(MII_RX_ER_GPIO_Port, &GPIO_InitStruct);

  /*Configure GPIO pins : PF2 PF1 PF0 PF3
                           PF5 PF4 PF13 PF14
                           PF12 PF15 PF11 */
  GPIO_InitStruct.Pin = GPIO_PIN_2|GPIO_PIN_1|GPIO_PIN_0|GPIO_PIN_3
                          |GPIO_PIN_5|GPIO_PIN_4|GPIO_PIN_13|GPIO_PIN_14
                          |GPIO_PIN_12|GPIO_PIN_15|GPIO_PIN_11;
  GPIO_InitStruct.Mode = GPIO_MODE_AF_PP;
  GPIO_InitStruct.Pull = GPIO_NOPULL;
  GPIO_InitStruct.Speed = GPIO_SPEED_FREQ_VERY_HIGH;
  GPIO_InitStruct.Alternate = GPIO_AF12_FMC;
  HAL_GPIO_Init(GPIOF, &GPIO_InitStruct);

  /*Configure GPIO pin : LD2_Pin */
  GPIO_InitStruct.Pin = LD2_Pin;
  GPIO_InitStruct.Mode = GPIO_MODE_OUTPUT_PP;
  GPIO_InitStruct.Pull = GPIO_NOPULL;
  GPIO_InitStruct.Speed = GPIO_SPEED_FREQ_LOW;
  HAL_GPIO_Init(LD2_GPIO_Port, &GPIO_InitStruct);

  /*Configure GPIO pin : LCD_INT_Pin */
  GPIO_InitStruct.Pin = LCD_INT_Pin;
  GPIO_InitStruct.Mode = GPIO_MODE_IT_RISING;
  GPIO_InitStruct.Pull = GPIO_NOPULL;
  HAL_GPIO_Init(LCD_INT_GPIO_Port, &GPIO_InitStruct);

  /*Configure GPIO pin : LCD_BL_Pin */
  GPIO_InitStruct.Pin = LCD_BL_Pin;
  GPIO_InitStruct.Mode = GPIO_MODE_INPUT;
  GPIO_InitStruct.Pull = GPIO_NOPULL;
  HAL_GPIO_Init(LCD_BL_GPIO_Port, &GPIO_InitStruct);

  /*Configure GPIO pins : PF6 PF7 PF10 */
  GPIO_InitStruct.Pin = GPIO_PIN_6|GPIO_PIN_7|GPIO_PIN_10;
  GPIO_InitStruct.Mode = GPIO_MODE_AF_PP;
  GPIO_InitStruct.Pull = GPIO_NOPULL;
  GPIO_InitStruct.Speed = GPIO_SPEED_FREQ_LOW;
  GPIO_InitStruct.Alternate = GPIO_AF9_QUADSPI;
  HAL_GPIO_Init(GPIOF, &GPIO_InitStruct);

  /*Configure GPIO pin : PC0 */
  GPIO_InitStruct.Pin = GPIO_PIN_0;
  GPIO_InitStruct.Mode = GPIO_MODE_ANALOG;
  GPIO_InitStruct.Pull = GPIO_NOPULL;
  HAL_GPIO_Init(GPIOC, &GPIO_InitStruct);

  /*Configure GPIO pin : PF9 */
  GPIO_InitStruct.Pin = GPIO_PIN_9;
  GPIO_InitStruct.Mode = GPIO_MODE_AF_PP;
  GPIO_InitStruct.Pull = GPIO_NOPULL;
  GPIO_InitStruct.Speed = GPIO_SPEED_FREQ_LOW;
  GPIO_InitStruct.Alternate = GPIO_AF10_QUADSPI;
  HAL_GPIO_Init(GPIOF, &GPIO_InitStruct);

  /*Configure GPIO pins : MII_MDC_Pin MII_TXD2_Pin MII_TX_CLK_Pin MII_RXD0_Pin
                           MII_RXD1_Pin */
  GPIO_InitStruct.Pin = MII_MDC_Pin|MII_TXD2_Pin|MII_TX_CLK_Pin|MII_RXD0_Pin
                          |MII_RXD1_Pin;
  GPIO_InitStruct.Mode = GPIO_MODE_AF_PP;
  GPIO_InitStruct.Pull = GPIO_NOPULL;
  GPIO_InitStruct.Speed = GPIO_SPEED_FREQ_LOW;
  GPIO_InitStruct.Alternate = GPIO_AF11_ETH;
  HAL_GPIO_Init(GPIOC, &GPIO_InitStruct);

  /*Configure GPIO pins : MII_CRS_Pin MII_COL_Pin */
  GPIO_InitStruct.Pin = MII_CRS_Pin|MII_COL_Pin;
  GPIO_InitStruct.Mode = GPIO_MODE_AF_PP;
  GPIO_InitStruct.Pull = GPIO_NOPULL;
  GPIO_InitStruct.Speed = GPIO_SPEED_FREQ_LOW;
  GPIO_InitStruct.Alternate = GPIO_AF11_ETH;
  HAL_GPIO_Init(GPIOH, &GPIO_InitStruct);

  /*Configure GPIO pins : MII_MDIO_Pin MII_RX_CLK_Pin MII_RX_DV_Pin */
  GPIO_InitStruct.Pin = MII_MDIO_Pin|MII_RX_CLK_Pin|MII_RX_DV_Pin;
  GPIO_InitStruct.Mode = GPIO_MODE_AF_PP;
  GPIO_InitStruct.Pull = GPIO_NOPULL;
  GPIO_InitStruct.Speed = GPIO_SPEED_FREQ_LOW;
  GPIO_InitStruct.Alternate = GPIO_AF11_ETH;
  HAL_GPIO_Init(GPIOA, &GPIO_InitStruct);

  /*Configure GPIO pins : PH5 PH6 PH7 */
  GPIO_InitStruct.Pin = GPIO_PIN_5|GPIO_PIN_6|GPIO_PIN_7;
  GPIO_InitStruct.Mode = GPIO_MODE_AF_PP;
  GPIO_InitStruct.Pull = GPIO_NOPULL;
  GPIO_InitStruct.Speed = GPIO_SPEED_FREQ_VERY_HIGH;
  GPIO_InitStruct.Alternate = GPIO_AF12_FMC;
  HAL_GPIO_Init(GPIOH, &GPIO_InitStruct);

  /*Configure GPIO pin : OTG_FS2_OverCurrent_Pin */
  GPIO_InitStruct.Pin = OTG_FS2_OverCurrent_Pin;
  GPIO_InitStruct.Mode = GPIO_MODE_IT_RISING;
  GPIO_InitStruct.Pull = GPIO_NOPULL;
  HAL_GPIO_Init(OTG_FS2_OverCurrent_GPIO_Port, &GPIO_InitStruct);

  /*Configure GPIO pin : PA6 */
  GPIO_InitStruct.Pin = GPIO_PIN_6;
  GPIO_InitStruct.Mode = GPIO_MODE_AF_PP;
  GPIO_InitStruct.Pull = GPIO_NOPULL;
  GPIO_InitStruct.Speed = GPIO_SPEED_FREQ_LOW;
  GPIO_InitStruct.Alternate = GPIO_AF9_TIM13;
  HAL_GPIO_Init(GPIOA, &GPIO_InitStruct);

  /*Configure GPIO pin : PH9 */
  GPIO_InitStruct.Pin = GPIO_PIN_9;
  GPIO_InitStruct.Mode = GPIO_MODE_AF_PP;
  GPIO_InitStruct.Pull = GPIO_NOPULL;
  GPIO_InitStruct.Speed = GPIO_SPEED_FREQ_LOW;
  GPIO_InitStruct.Alternate = GPIO_AF14_LTDC;
  HAL_GPIO_Init(GPIOH, &GPIO_InitStruct);

  /*Configure GPIO pin : PD11 */
  GPIO_InitStruct.Pin = GPIO_PIN_11;
  GPIO_InitStruct.Mode = GPIO_MODE_AF_PP;
  GPIO_InitStruct.Pull = GPIO_NOPULL;
  GPIO_InitStruct.Speed = GPIO_SPEED_FREQ_LOW;
  GPIO_InitStruct.Alternate = GPIO_AF9_QUADSPI;
  HAL_GPIO_Init(GPIOD, &GPIO_InitStruct);

  /*Configure GPIO pins : MII_RX_D3_Pin MII_RX_D2_Pin */
  GPIO_InitStruct.Pin = MII_RX_D3_Pin|MII_RX_D2_Pin;
  GPIO_InitStruct.Mode = GPIO_MODE_AF_PP;
  GPIO_InitStruct.Pull = GPIO_NOPULL;
  GPIO_InitStruct.Speed = GPIO_SPEED_FREQ_LOW;
  GPIO_InitStruct.Alternate = GPIO_AF11_ETH;
  HAL_GPIO_Init(GPIOB, &GPIO_InitStruct);

  /*Configure GPIO pin : LD1_Pin */
  GPIO_InitStruct.Pin = LD1_Pin;
  GPIO_InitStruct.Mode = GPIO_MODE_OUTPUT_PP;
  GPIO_InitStruct.Pull = GPIO_NOPULL;
  GPIO_InitStruct.Speed = GPIO_SPEED_FREQ_LOW;
  HAL_GPIO_Init(LD1_GPIO_Port, &GPIO_InitStruct);

  /*Configure GPIO pin : LCD_RST_Pin */
  GPIO_InitStruct.Pin = LCD_RST_Pin;
  GPIO_InitStruct.Mode = GPIO_MODE_OUTPUT_PP;
  GPIO_InitStruct.Pull = GPIO_NOPULL;
  GPIO_InitStruct.Speed = GPIO_SPEED_FREQ_LOW;
  HAL_GPIO_Init(LCD_RST_GPIO_Port, &GPIO_InitStruct);

  /*Configure GPIO pin : PB15 */
  GPIO_InitStruct.Pin = GPIO_PIN_15;
  GPIO_InitStruct.Mode = GPIO_MODE_AF_PP;
  GPIO_InitStruct.Pull = GPIO_NOPULL;
  GPIO_InitStruct.Speed = GPIO_SPEED_FREQ_LOW;
  GPIO_InitStruct.Alternate = GPIO_AF5_SPI2;
  HAL_GPIO_Init(GPIOB, &GPIO_InitStruct);

  /*AnalogSwitch Config */
  HAL_SYSCFG_AnalogSwitchConfig(SYSCFG_SWITCH_PA0, SYSCFG_SWITCH_PA0_OPEN);

  /*AnalogSwitch Config */
  HAL_SYSCFG_AnalogSwitchConfig(SYSCFG_SWITCH_PA1, SYSCFG_SWITCH_PA1_OPEN);

  /* USER CODE BEGIN MX_GPIO_Init_2 */
  //Config PE3 on connector CN2. Pa3cio.
  GPIO_InitStruct.Pin = GPIO_PIN_3;
  GPIO_InitStruct.Mode = GPIO_MODE_OUTPUT_PP;
  GPIO_InitStruct.Pull = GPIO_NOPULL;
  GPIO_InitStruct.Speed = GPIO_SPEED_FREQ_LOW;
  HAL_GPIO_Init(GPIOE, &GPIO_InitStruct);
/* USER CODE END MX_GPIO_Init_2 */
}

/* USER CODE BEGIN 4 */
ai_bool pa3_ai_network_init(void)
{
    // Create and initialize the network instance
    ai_error err = ai_network_create(&network, AI_NETWORK_DATA_CONFIG);
    if ((err.code != AI_ERROR_CODE_NONE) && (err.type != AI_ERROR_NONE)) {
        // Handle error: failed to create the network instance
    	__NOP();
        return false;
    }

    // Initialize the network with the activation memory buffer

    ai_network_params params = {
    		AI_NETWORK_DATA_WEIGHTS(ai_network_data_weights_get()),  	// Macro for getting weights
    		AI_NETWORK_DATA_ACTIVATIONS(data_activations0[0])  		// Macro for setting activations buffer
    };

    if (!ai_network_init(network, &params)) {
        // Handle error: failed to initialize the network
    	ai_error err = ai_network_get_error(network);
    	printf("Network initialization error. Type: %d, Code: %d\n", err.type, err.code);
    	__NOP();
        return false;
    }
    return true;
}

ai_i32 pa3_ai_network_inference(ai_i8 *input_data, ai_i8 *output_data)
{
        // Configure the input and output buffers

	// NHWC (Batch, Height, Width, Channels): This is the most common format for images
	// Define input dimensions (batch, height, width, channels) ???
	//ai_shape_dimension input_shape_data[] = { 1, AI_NETWORK_IN_1_HEIGHT, AI_NETWORK_IN_1_WIDTH, AI_NETWORK_IN_1_CHANNEL };

	// Look in network.c:
	/*
	 * Tensor #12
		AI_TENSOR_OBJ_DECLARE(
  	  	  input_output, AI_STATIC,
  	  	  12, 0x1,
  	  	  AI_SHAPE_INIT(4, 1, 28, 28, 1), AI_STRIDE_INIT(4, 1, 1, 28, 784),
  	  	  1, &input_output_array, &input_output_array_intq)
	 */
	ai_shape_dimension input_shape_data[] = { 1, 28, 28, 1 };
	// Initialize the input buffer
	ai_buffer ai_input[AI_NETWORK_IN_NUM] = {
	{
		.format = AI_NETWORK_IN_1_FORMAT,  		// Set the format (AI_BUFFER_FORMAT_S8)
		.data = AI_HANDLE_PTR(input_data),  	// Pointer to the input data
		.meta_info = NULL,  					// No metadata info
		.flags = 0,  							// No specific flags
		.size = AI_NETWORK_IN_1_SIZE,  			// Number of elements in the buffer
		.shape = {  							// Input shape: [1, 1, 28, 28] based on the network input size
			.size = 4,  						// Number of dimensions
			.data = input_shape_data
		}
	}
	};

	// Define output dimensions (batch, number of classes)
	// Look in network.c
	/*
	 * Tensor #10
		AI_TENSOR_OBJ_DECLARE(
  	  	  output_QuantizeLinear_Input_bias, AI_STATIC,
  	  	  10, 0x0,
  	  	  AI_SHAPE_INIT(4, 1, 10, 1, 1), AI_STRIDE_INIT(4, 4, 4, 40, 40),
  	  	  1, &output_QuantizeLinear_Input_bias_array, NULL)
	 */
	ai_shape_dimension output_shape_data[] = { 1, AI_NETWORK_OUT_1_SIZE, 1, 1};

	// Output buffer initialization
	ai_buffer ai_output[AI_NETWORK_OUT_NUM] = {
        {
		.format = AI_NETWORK_OUT_1_FORMAT,
		.data = AI_HANDLE_PTR(output_data),  	// Assuming output_data points to where the output will be stored
		.meta_info = NULL,
		.flags = 0,
		.size = AI_NETWORK_OUT_1_SIZE,       	// Total number of elements (10 in your case)
		.shape = {
			//.size = 2,
			.size = 4,
			.data = output_shape_data           // Batch size = 1, Number of classes = 10
		}
	}
	};

    // Run the network
    ai_i32 nbatch = ai_network_run(network, ai_input, ai_output);

    if (nbatch != 1) {
        // Handle error: inference failed
    	ai_error err = ai_network_get_error(network);
    	printf("Inference failed. Error type: %d, Error code: %d\n", err.type, err.code);
    	__NOP();
        return -1;
    }

    return 0;  // Inference successful
}

void pa3_run_model_on_test_dataset(void){

	// Loop over all MNIST_TEST_SUBSET_SIZE test samples
	UART_SendString(&huart3, "\n\nRunning inference...\n");
	sprintf(buffer, "   MNIST test dataset size: %d \n", MNIST_TEST_SUBSET_SIZE);
	UART_SendString(&huart3, buffer);
	for (int i = 0; i < MNIST_TEST_SUBSET_SIZE; i++) {
	  // Copy the test sample data (uint8) into network input buffer (int8)
	  for (int j = 0; j < AI_NETWORK_IN_1_SIZE; j++) {
		  network_input[j] = (ai_i8)(mnist_test[i][j]);
	  }

	  // Run inference on the current sample
	  HAL_GPIO_WritePin(GPIOE, GPIO_PIN_3, GPIO_PIN_SET);
	  if (pa3_ai_network_inference(network_input, network_output) != 0) {
		  //printf("Inference failed for sample %d\n", i);
		  __NOP();
		  UART_SendString(&huart3, "Error running inference.");
		  return -1;
	  }
	  HAL_GPIO_WritePin(GPIOE, GPIO_PIN_3, GPIO_PIN_RESET);

	  int8_t max = -127;
	  int8_t digit = 0;
	  for(int k = 0; k < AI_NETWORK_OUT_1_SIZE ; k++) {
		  if (network_output[k] >= max){
			  max = network_output[k];
			  digit = k;
		  }
	  }
	  recognized_digits[i] = digit;
	  sprintf(buffer, "   Data %d: Recognized character: %d Label: %d", i, digit, mnist_test_labels[i]);
	  UART_SendString(&huart3, buffer);
	  if (digit != mnist_test_labels[i]){
		  UART_SendString(&huart3, " *** Error \n");
	  }
	  else UART_SendString(&huart3, "\n");
	  HAL_Delay(20);
	}

	for(int i = 0; i < MNIST_TEST_SUBSET_SIZE; i++) {
	  if (recognized_digits[i] == mnist_test_labels[i]) {
		  success ++;
	  }
	}
	accuracy = (float)success / (float)MNIST_TEST_SUBSET_SIZE;
	//printf("Accuracy = %f", accuracy);
	sprintf(buffer, "\n\nNetwork accuracy: %f", accuracy);
	UART_SendString(&huart3, buffer);
}

void UART_SendString(UART_HandleTypeDef* huart, const char *str) {
    // Get the length of the string
    size_t len = strlen(str);

    // Transmit the string over UART3
    HAL_UART_Transmit(huart, (uint8_t *)str, len, HAL_MAX_DELAY);
}
/* USER CODE END 4 */

 /* MPU Configuration */

void MPU_Config(void)
{
  MPU_Region_InitTypeDef MPU_InitStruct = {0};

  /* Disables the MPU */
  HAL_MPU_Disable();

  /** Initializes and configures the Region and the memory to be protected
  */
  MPU_InitStruct.Enable = MPU_REGION_ENABLE;
  MPU_InitStruct.Number = MPU_REGION_NUMBER0;
  MPU_InitStruct.BaseAddress = 0x90000000;
  MPU_InitStruct.Size = MPU_REGION_SIZE_128MB;
  MPU_InitStruct.SubRegionDisable = 0x0;
  MPU_InitStruct.TypeExtField = MPU_TEX_LEVEL0;
  MPU_InitStruct.AccessPermission = MPU_REGION_FULL_ACCESS;
  MPU_InitStruct.DisableExec = MPU_INSTRUCTION_ACCESS_ENABLE;
  MPU_InitStruct.IsShareable = MPU_ACCESS_NOT_SHAREABLE;
  MPU_InitStruct.IsCacheable = MPU_ACCESS_CACHEABLE;
  MPU_InitStruct.IsBufferable = MPU_ACCESS_BUFFERABLE;

  HAL_MPU_ConfigRegion(&MPU_InitStruct);

  /** Initializes and configures the Region and the memory to be protected
  */
  MPU_InitStruct.Number = MPU_REGION_NUMBER1;
  MPU_InitStruct.BaseAddress = 0xD0000000;
  MPU_InitStruct.Size = MPU_REGION_SIZE_8MB;

  HAL_MPU_ConfigRegion(&MPU_InitStruct);
  /* Enables the MPU */
  HAL_MPU_Enable(MPU_PRIVILEGED_DEFAULT);

}

void Error_Handler(void)
{
  __disable_irq();
  while (1)
  {
  }
}
